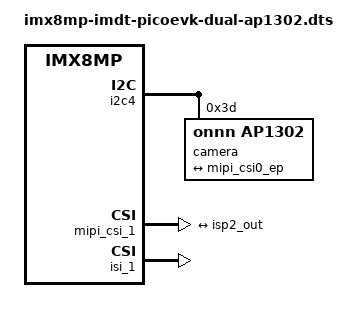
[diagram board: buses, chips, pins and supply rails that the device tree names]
// SPDX-License-Identifier: (GPL-2.0+ OR MIT)
/*
 * Copyright 2019 NXP
 */

/dts-v1/;

#include <dt-bindings/usb/pd.h>
#include "imx8mp-imdt-picoevk.dts"

&i2c4 {

	camera@3d {
		compatible = "onnn,ap1302";
		reg = <0x3d>;

		clocks = <&clk IMX8MP_CLK_IPP_DO_CLKO2>;
		clock-names = "csi_mclk";
		assigned-clocks = <&clk IMX8MP_CLK_IPP_DO_CLKO2>;
		assigned-clock-parents = <&clk IMX8MP_CLK_24M>;
		assigned-clock-rates = <24000000>;

		port {
			isp2_out: endpoint {
				remote-endpoint = <&mipi_csi0_ep>;
				data-lanes = <1 2 3 4>;
			};
		};

		sensors {
			#address-cells = <1>;
			#size-cells = <0>;

			onnn,model = "onnn,ar1335";

			sensor@0 {
				reg = <0>;
			};
		};
	};
};

&mipi_csi_1 {
	#address-cells = <1>;
	#size-cells = <0>;
	status = "okay";

	port@1 {
		reg = <1>;
		mipi_csi1_ep: endpoint {
			remote-endpoint = <&isp2_out>;
			data-lanes = <4>;
			csis-hs-settle = <13>;
			csis-clk-settle = <2>;
			csis-wclk;
		};
	};
};

&isi_1 {
	status = "okay";

	cap_device {
		status = "okay";
	};
};
